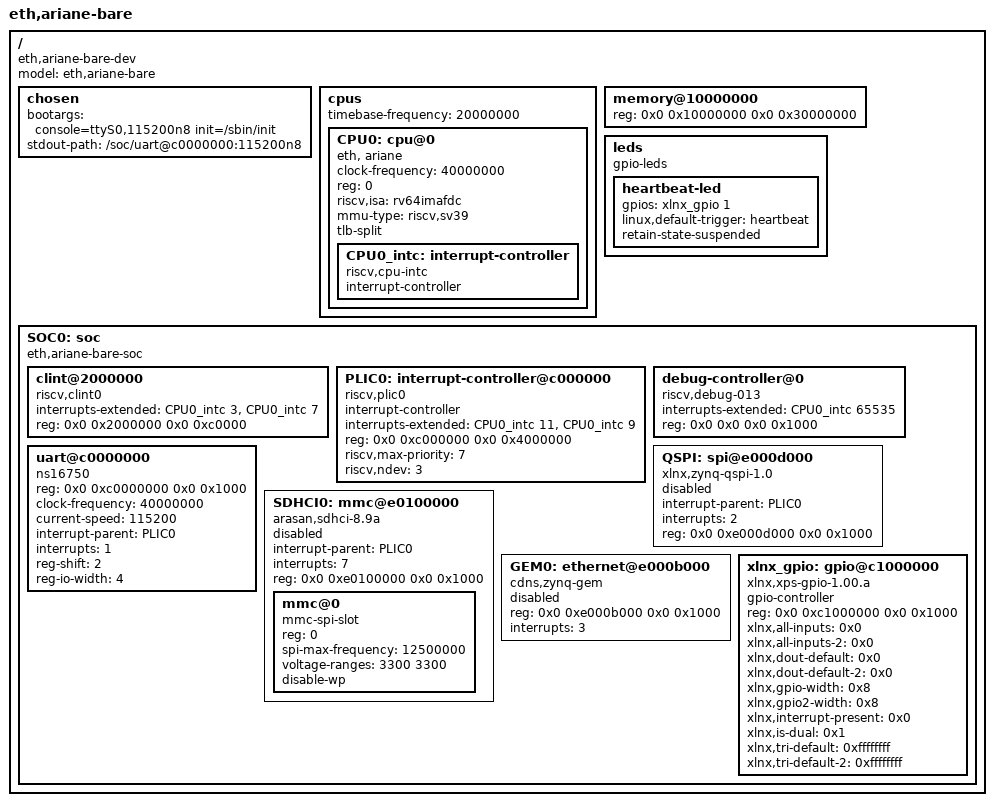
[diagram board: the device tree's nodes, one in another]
/dts-v1/;

/ {
  #address-cells = <2>;
  #size-cells = <2>;
  compatible = "eth,ariane-bare-dev";
  model = "eth,ariane-bare";
  chosen {
    bootargs = "console=ttyS0,115200n8 init=/sbin/init";
    stdout-path = "/soc/uart@c0000000:115200n8";
  };
  cpus {
    #address-cells = <1>;
    #size-cells = <0>;
    timebase-frequency = <20000000>; // 20 MHz
    CPU0: cpu@0 {
      clock-frequency = <40000000>; // 40 MHz
      device_type = "cpu";
      reg = <0>;
      status = "okay";
      compatible = "eth, ariane", "riscv";
      riscv,isa = "rv64imafdc";
      mmu-type = "riscv,sv39";
      tlb-split;

      CPU0_intc: interrupt-controller {
        #interrupt-cells = <1>;
        interrupt-controller;
        compatible = "riscv,cpu-intc";
      };
    };
  };
  memory@10000000 {
    device_type = "memory";
    reg = <0x0 0x10000000 0x0 0x30000000>;
  };
  leds {
    compatible = "gpio-leds";
    heartbeat-led {
      gpios = <&xlnx_gpio 1 0>;
      linux,default-trigger = "heartbeat";
      retain-state-suspended;
    };
  };
  SOC0: soc {
    #address-cells = <2>;
    #size-cells = <2>;
    compatible = "eth,ariane-bare-soc", "simple-bus";
    ranges;
    clint@2000000 {
      compatible = "riscv,clint0";
      interrupts-extended = <&CPU0_intc 3 &CPU0_intc 7>;
      reg = <0x0 0x2000000 0x0 0xc0000>;
      reg-names = "control";
    };
    PLIC0: interrupt-controller@c000000 {
      #address-cells = <0>;
      #interrupt-cells = <1>;
      compatible = "riscv,plic0";
      interrupt-controller;
      interrupts-extended = <&CPU0_intc 11 &CPU0_intc 9>;
      reg = <0x0 0xc000000 0x0 0x4000000>;
      riscv,max-priority = <7>;
      riscv,ndev = <3>;
    };
    debug-controller@0 {
      compatible = "riscv,debug-013";
      interrupts-extended = <&CPU0_intc 65535>;
      reg = <0x0 0x0 0x0 0x1000>;
      reg-names = "control";
    };
    uart@c0000000 {
      compatible = "ns16750";
      reg = <0x0 0xc0000000 0x0 0x1000>;
      clock-frequency = <40000000>;
      current-speed = <115200>;
      interrupt-parent = <&PLIC0>;
      interrupts = <1>;
      reg-shift = <2>; // regs are spaced on 32 bit boundary
      reg-io-width = <4>; // only 32-bit access are supported
    };

    QSPI: spi@e000d000 {
      compatible = "xlnx,zynq-qspi-1.0";
      #address-cells = <1>;
      #size-cells = <0>;
      status = "disabled";
      interrupt-parent = <&PLIC0>;
      interrupts = <2>;
      reg = <0x0 0xe000d000 0x0 0x1000>;
    };

    SDHCI0: mmc@e0100000 {
      compatible = "arasan,sdhci-8.9a";
      status = "disabled";
      interrupt-parent = <&PLIC0>;
      interrupts = <7>;
      reg = <0x0 0xe0100000 0x0 0x1000>;

      mmc@0 {
        compatible = "mmc-spi-slot";
        reg = <0>;
        spi-max-frequency = <12500000>;
        voltage-ranges = <3300 3300>;
        disable-wp;
      };
    };

    GEM0: ethernet@e000b000 {
      compatible = "cdns,zynq-gem", "cdns,gem";
      reg = <0x0 0xe000b000 0x0 0x1000>;
      status = "disabled";
      interrupts = <3>;
      #address-cells = <1>;
      #size-cells = <0>;
    };

    xlnx_gpio: gpio@c1000000 {
      #gpio-cells = <2>;
      compatible = "xlnx,xps-gpio-1.00.a";
      gpio-controller ;
      reg = <0x0 0xc1000000 0x0 0x1000 >;
      xlnx,all-inputs = <0x0>;
      xlnx,all-inputs-2 = <0x0>;
      xlnx,dout-default = <0x0>;
      xlnx,dout-default-2 = <0x0>;
      xlnx,gpio-width = <0x8>;
      xlnx,gpio2-width = <0x8>;
      xlnx,interrupt-present = <0x0>;
      xlnx,is-dual = <0x1>;
      xlnx,tri-default = <0xffffffff>;
      xlnx,tri-default-2 = <0xffffffff>;
    };
  };
};
